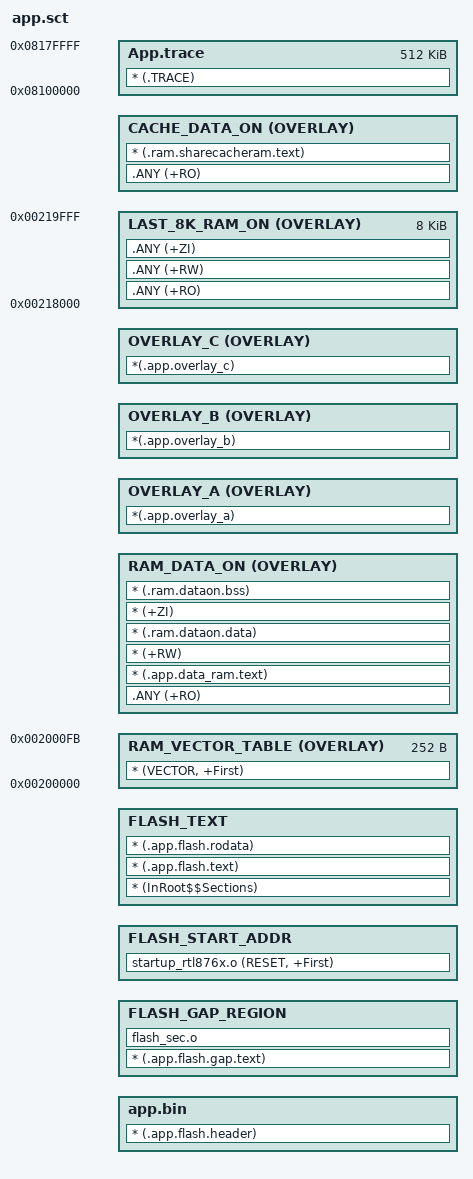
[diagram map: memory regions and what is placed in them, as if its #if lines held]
#! armcc -E
#include "..\mem_config.h"

; *************************************************************
; *** Scatter-Loading Description File generated by uVision ***
; *************************************************************

; APP RAM definitions
#define APP_DATA_ON_ADR                   APP_GLOBAL_ADDR
#define APP_DATA_ON_SIZE                  APP_GLOBAL_SIZE

#define CACHE_DATA_ON_ADR                 SHARE_CACHE_RAM_ADDR
#define CACHE_DATA_ON_SIZE                SHARE_CACHE_RAM_SIZE

#if (SHUTDOWN_DATARAM_SIZE == 32*1024)
#define LAST_8K_DATA_ON_ADR               (0x218000)
#define LAST_8K_DATA_ON_SIZE              (8 * 1024)
#endif

#if (BUILD_BANK == 0)
#define APP_FLASH_ADR                     BANK0_APP_ADDR
#else
#define APP_FLASH_ADR                     BANK1_APP_ADDR
#endif
#define APP_FLASH_SIZE                    BANK0_APP_SIZE

#define APP_TRACE_ADR                     0x08100000
#define APP_TRACE_SIZE                    (0x80000)


LOAD_FLASH APP_FLASH_ADR APP_FLASH_SIZE
{
    app.bin +0
    {
        * (.app.flash.header)
    }

#if (FEATURE_FLASH_SEC == 1)   
    FLASH_GAP_REGION +0
    {
        * (.app.flash.gap.text)
        flash_sec.o
    }

    FLASH_START_ADDR +0 ALIGN 0x1000
#else 
    FLASH_START_ADDR +0
#endif
    {
        startup_rtl876x.o (RESET, +First)
    }

    FLASH_TEXT +0
    {
#if FEATURE_RAM_CODE
        * (InRoot$$Sections)
#else
        .ANY (+RO)
#endif
        * (.app.flash.text)
        * (.app.flash.rodata)
    }

    RAM_VECTOR_TABLE 0x00200000 OVERLAY 0xFC ; 63 ISRs
    {
        * (VECTOR, +First)
    }

    RAM_DATA_ON APP_DATA_ON_ADR OVERLAY (APP_DATA_ON_SIZE)
    {
#if FEATURE_RAM_CODE
        .ANY (+RO)
#endif
        * (.app.data_ram.text)
        * (+RW)
        * (.ram.dataon.data)
        * (+ZI)
        * (.ram.dataon.bss)
    }

; overlay section begin
    OVERLAY_A ImageLimit(RAM_DATA_ON) OVERLAY
    {
        *(.app.overlay_a)
    }

    OVERLAY_B ImageLimit(RAM_DATA_ON) OVERLAY
    {
        *(.app.overlay_b)
    }
    OVERLAY_C ImageLimit(RAM_DATA_ON) OVERLAY
    {
        *(.app.overlay_c)
    }
; overlay section end

#if (SHUTDOWN_DATARAM_SIZE == 32 * 1024)
    LAST_8K_RAM_ON LAST_8K_DATA_ON_ADR OVERLAY (LAST_8K_DATA_ON_SIZE)
    {
#if FEATURE_RAM_CODE
        .ANY (+RO)
#endif
        .ANY (+RW)
        .ANY (+ZI)
    }
#endif

#if (FEATURE_FLASH_SEC == 1)   
    ScatterAssert((ImageLength(FLASH_GAP_REGION) + ImageLength(app.bin)) <= (0x1000))
#endif

#if (SHUTDOWN_DATARAM_SIZE == 32 * 1024)
    ScatterAssert((ImageLength(RAM_DATA_ON) + ImageLength(OVERLAY_A) + ImageLength(LAST_8K_RAM_ON)) <= (APP_DATA_ON_SIZE + LAST_8K_DATA_ON_SIZE))
    ScatterAssert((ImageLength(RAM_DATA_ON) + ImageLength(OVERLAY_B) + ImageLength(LAST_8K_RAM_ON)) <= (APP_DATA_ON_SIZE + LAST_8K_DATA_ON_SIZE))
    ScatterAssert((ImageLength(RAM_DATA_ON) + ImageLength(OVERLAY_C) + ImageLength(LAST_8K_RAM_ON))  <= (APP_DATA_ON_SIZE + LAST_8K_DATA_ON_SIZE))
#else
    ScatterAssert((ImageLength(RAM_DATA_ON) + ImageLength(OVERLAY_A)) <= (APP_DATA_ON_SIZE))
    ScatterAssert((ImageLength(RAM_DATA_ON) + ImageLength(OVERLAY_B)) <= (APP_DATA_ON_SIZE))
    ScatterAssert((ImageLength(RAM_DATA_ON) + ImageLength(OVERLAY_C)) <= (APP_DATA_ON_SIZE))
#endif

    CACHE_DATA_ON CACHE_DATA_ON_ADR OVERLAY CACHE_DATA_ON_SIZE
    {
#if FEATURE_RAM_CODE
        .ANY (+RO)
#endif
        * (.ram.sharecacheram.text)
    }
}

LOAD_APP_TRACE APP_TRACE_ADR APP_TRACE_SIZE
{
    App.trace APP_TRACE_ADR APP_TRACE_SIZE
    {
        * (.TRACE)
    }
}
